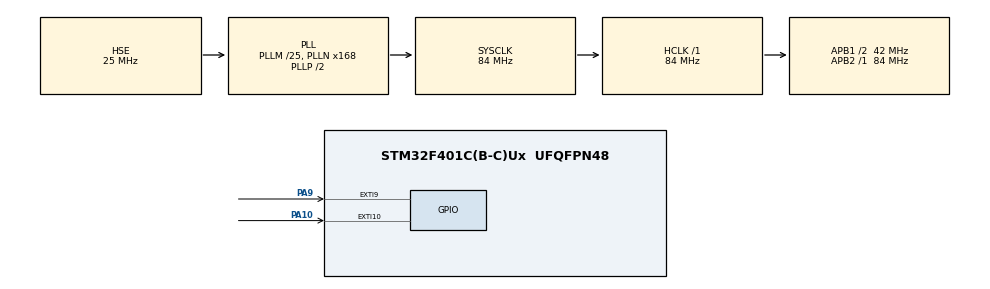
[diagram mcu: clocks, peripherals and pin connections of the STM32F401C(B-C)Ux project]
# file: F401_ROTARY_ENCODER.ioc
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Mcu.Family=STM32F4
Mcu.Name=STM32F401C(B-C)Ux
Mcu.Package=UFQFPN48
NVIC.EXTI15_10_IRQn=true\:0\:0\:false\:false\:true\:true\:true\:true
NVIC.EXTI9_5_IRQn=true\:0\:0\:false\:false\:true\:true\:true\:true
NVIC.PriorityGroup=NVIC_PRIORITYGROUP_4
PA10.GPIO_ModeDefaultEXTI=GPIO_MODE_IT_RISING_FALLING
PA10.GPIO_PuPd=GPIO_PULLUP
PA10.Signal=GPXTI10
PA9.GPIO_ModeDefaultEXTI=GPIO_MODE_IT_RISING_FALLING
PA9.GPIO_PuPd=GPIO_PULLUP
PA9.Signal=GPXTI9
PH0\ -\ OSC_IN.Mode=HSE-External-Oscillator
PH0\ -\ OSC_IN.Signal=RCC_OSC_IN
PH1\ -\ OSC_OUT.Mode=HSE-External-Oscillator
PH1\ -\ OSC_OUT.Signal=RCC_OSC_OUT
ProjectManager.HeapSize=0x200
ProjectManager.StackSize=0x400
ProjectManager.TargetToolchain=STM32CubeIDE
RCC.48MHZClocksFreq_Value=42000000
RCC.AHBFreq_Value=84000000
RCC.APB1CLKDivider=RCC_HCLK_DIV2
RCC.APB1Freq_Value=42000000
RCC.APB1TimFreq_Value=84000000
RCC.APB2Freq_Value=84000000
RCC.APB2TimFreq_Value=84000000
RCC.CortexFreq_Value=84000000
RCC.HCLKFreq_Value=84000000
RCC.HSE_VALUE=25000000
RCC.HSI_VALUE=16000000
RCC.LSE_VALUE=32768
RCC.PLLM=25
RCC.PLLN=168
RCC.PLLSourceVirtual=RCC_PLLSOURCE_HSE
RCC.SYSCLKFreq_VALUE=84000000
RCC.SYSCLKSource=RCC_SYSCLKSOURCE_PLLCLK
RCC.VCOOutputFreq_Value=168000000
board=custom

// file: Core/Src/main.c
/* USER CODE BEGIN Header */
/**
  ******************************************************************************
  * @file           : main.c
  * @brief          : Main program body
  ******************************************************************************
  * @attention
  *
  * Copyright (c) 2024 STMicroelectronics.
  * All rights reserved.
  *
  * This software is licensed under terms that can be found in the LICENSE file
  * in the root directory of this software component.
  * If no LICENSE file comes with this software, it is provided AS-IS.
  *
  ******************************************************************************
  */
/* USER CODE END Header */
#include "main.h"
#include "gpio.h"

/* USER CODE BEGIN PD */

#define SPR 800
#define EPR 2400
#define TIM_FREQ 1000000
#define ALPHA (2*3.14159/SPR)
#define PI 3.14159

#define chA_pin GPIO_PIN_9
#define chB_pin GPIO_PIN_10
#define chAB_gpio_port GPIOA

#define chA1_pin GPIO_PIN_11
#define chB1_pin GPIO_PIN_12

#define wheel_radius_encoder 0.03 //m

uint32_t sample_time = 0;
int get_value = 0;

/* USER CODE END PD */

void SystemClock_Config(void);

/* USER CODE BEGIN 0 */

typedef struct{
  long counter;
  GPIO_PinState lastA;
  GPIO_PinState lastB;
  double distand ;
  double last_en_co;
  double angle;
}encoder;
encoder enc1;

void read_encoder(encoder *Encoder, GPIO_PinState chA, GPIO_PinState ChB){
  if(chA != Encoder->lastA){
    Encoder->lastA = chA;
    if(chA != ChB){
      Encoder->counter++;
    }else {
      Encoder->counter--;
    }

  }
  if(ChB != Encoder->lastB){
    Encoder->lastB = ChB;
    if(ChB == chA){
      Encoder->counter++;
    }else {
      Encoder->counter--;
    }
  }
}

/* USER CODE END 0 */

int main(void)
{

  /* MCU Configuration--------------------------------------------------------*/

  /* Reset of all peripherals, Initializes the Flash interface and the Systick. */
  HAL_Init();

  /* Configure the system clock */
  SystemClock_Config();

  /* Initialize all configured peripherals */
  MX_GPIO_Init();
  /* USER CODE BEGIN 2 */

//  HAL_TIM_Base_Start_IT(&htim5);

  /* USER CODE END 2 */

  /* Infinite loop */
  while (1)
  {

    /* USER CODE BEGIN 3 */
	  if ( HAL_GetTick() - sample_time >= 10){
		  sample_time = HAL_GetTick();
		  get_value = enc1.counter;
	  }

  }
  /* USER CODE END 3 */
}

void SystemClock_Config(void)
{
  RCC_OscInitTypeDef RCC_OscInitStruct = {0};
  RCC_ClkInitTypeDef RCC_ClkInitStruct = {0};

  /** Configure the main internal regulator output voltage
  */
  __HAL_RCC_PWR_CLK_ENABLE();
  __HAL_PWR_VOLTAGESCALING_CONFIG(PWR_REGULATOR_VOLTAGE_SCALE2);

  /** Initializes the RCC Oscillators according to the specified parameters
  * in the RCC_OscInitTypeDef structure.
  */
  RCC_OscInitStruct.OscillatorType = RCC_OSCILLATORTYPE_HSE;
  RCC_OscInitStruct.HSEState = RCC_HSE_ON;
  RCC_OscInitStruct.PLL.PLLState = RCC_PLL_ON;
  RCC_OscInitStruct.PLL.PLLSource = RCC_PLLSOURCE_HSE;
  RCC_OscInitStruct.PLL.PLLM = 25;
  RCC_OscInitStruct.PLL.PLLN = 168;
  RCC_OscInitStruct.PLL.PLLP = RCC_PLLP_DIV2;
  RCC_OscInitStruct.PLL.PLLQ = 4;
  if (HAL_RCC_OscConfig(&RCC_OscInitStruct) != HAL_OK)
  {
    Error_Handler();
  }

  /** Initializes the CPU, AHB and APB buses clocks
  */
  RCC_ClkInitStruct.ClockType = RCC_CLOCKTYPE_HCLK|RCC_CLOCKTYPE_SYSCLK
                              |RCC_CLOCKTYPE_PCLK1|RCC_CLOCKTYPE_PCLK2;
  RCC_ClkInitStruct.SYSCLKSource = RCC_SYSCLKSOURCE_PLLCLK;
  RCC_ClkInitStruct.AHBCLKDivider = RCC_SYSCLK_DIV1;
  RCC_ClkInitStruct.APB1CLKDivider = RCC_HCLK_DIV2;
  RCC_ClkInitStruct.APB2CLKDivider = RCC_HCLK_DIV1;

  if (HAL_RCC_ClockConfig(&RCC_ClkInitStruct, FLASH_LATENCY_2) != HAL_OK)
  {
    Error_Handler();
  }
}

/* USER CODE BEGIN 4 */
void HAL_GPIO_EXTI_Callback(uint16_t GPIO_Pin){
	if(GPIO_Pin == chA_pin||chB_pin){
		read_encoder(&enc1, HAL_GPIO_ReadPin(chAB_gpio_port, chA_pin), HAL_GPIO_ReadPin(chAB_gpio_port, chB_pin));
	}
}

/* USER CODE END 4 */

void Error_Handler(void)
{
  __disable_irq();
  while (1)
  {
  }
}
